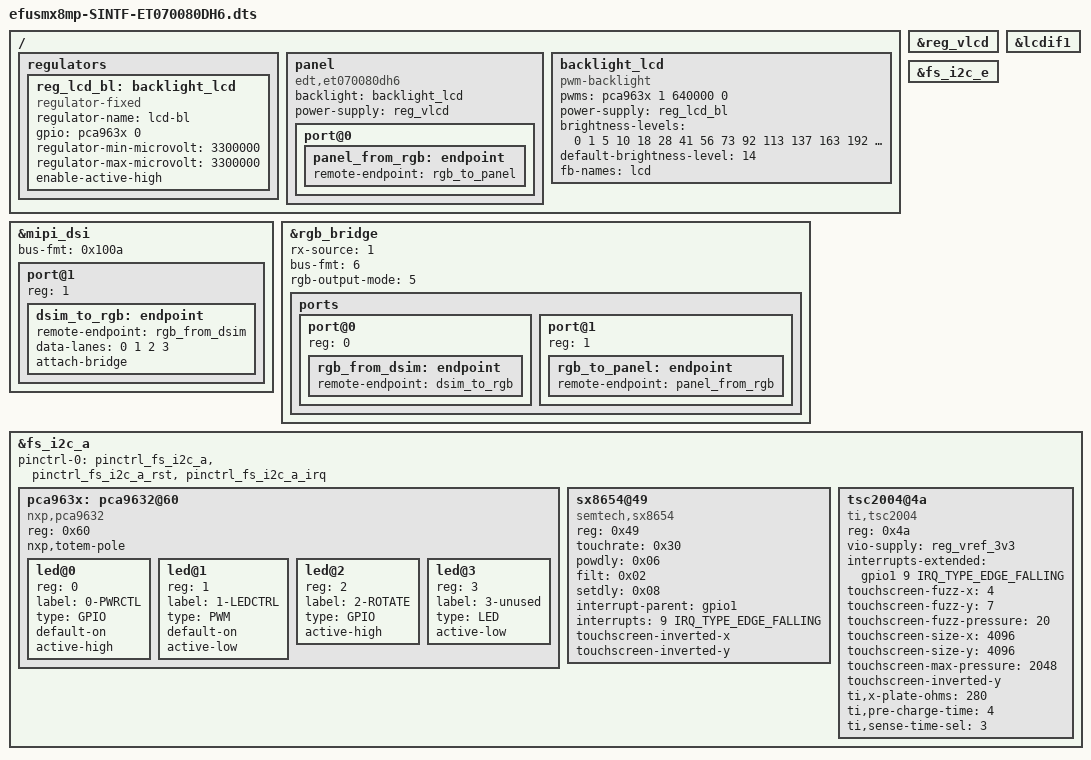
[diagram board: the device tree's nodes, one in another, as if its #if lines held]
/*
* Copyright (C) 2023 F&S Elektronik Systeme GmbH
*
* This program is free software; you can redistribute it and/or modify
* it under the terms of the GNU General Public License version 2 as
* published by the Free Software Foundation.
*/

/dts-v1/;

//#define CONFIG_EFUSMX8MP_4WTOUCH_SX8655_RGBADAPTER_EDT1
#define CONFIG_EFUSMX8MP_4WTOUCH_TSC2004_RGBADAPTER_EDT2

#include "efusmx8mp-SINTF.dts"

/{

	regulators {
    	reg_lcd_bl: backlight_lcd {
			compatible = "regulator-fixed";
			regulator-name = "lcd-bl";
			gpio = <&pca963x 0 0>;
			regulator-min-microvolt = <3300000>;
			regulator-max-microvolt = <3300000>;
			enable-active-high;
		};
    };

    panel: panel {
		compatible = "edt,et070080dh6";
		backlight = <&backlight_lcd>;
		power-supply = <&reg_vlcd>;

		port@0 {
			panel_from_rgb: endpoint {
				remote-endpoint = <&rgb_to_panel>;
			};
		};
	};

    backlight_lcd: backlight_lcd {
		compatible = "pwm-backlight";
		pwms = <&pca963x 1 640000 0>;
		power-supply = <&reg_lcd_bl>;
		brightness-levels = <0 1 5 10 18 28 41 56
				     73 92 113 137 163 192 222 255>;
		default-brightness-level = <14>;
		fb-names = "lcd";
	};
};

&reg_vlcd { status = "okay"; };
&lcdif1 { status = "okay"; };

&mipi_dsi {

	status = "okay";

	bus-fmt = <0x100a>; /*MEDIA_BUS_FMT_RGB888_1X24*/
	port@1{
		reg = <1>;
		dsim_to_rgb: endpoint {
			remote-endpoint = <&rgb_from_dsim>;
			data-lanes = <0 1 2 3>;
			attach-bridge;
		};
	};
};

&fs_i2c_e { status = "okay"; };

&rgb_bridge {

    /* 0 = LVDS, 1 = MIPI, 2 = TTL */
    rx-source = /bits/ 8 <1>;
    /* optional: normally taken from simple panel display but can be
        * overwritten by bus-fmt flag: 6 = RGB666, 8 = RGB888
        */
    bus-fmt = /bits/ 8 <6>;
    /* PCLK will inverted because dotclock polarity from sec_mipi_dsim-imx
        * is set to neg edge. The display needs dotclock pos edge therefore
        * we inverte dotclock polarity.
        */
    //pclk-invert;

    /* s. datasheet reg 0x856d rgd_ttl_tx_24B_mode_sel
        * 	0 - output 3 channel 8 bit data
        * 	1 - output 2 channel 12 bit data
        *  ...
        *  4 - output 3 channel 6 bit (high 18 bit active)
        *  5 - output 3 channel 6 bit (low 18 bit active)
        *  ...
        * */
    rgb-output-mode = /bits/ 8 <5>;

	status = "okay";
    ports {
        #address-cells = <1>;
        #size-cells = <0>;
        port@0 {
            reg = <0>;
            rgb_from_dsim: endpoint {
                remote-endpoint = <&dsim_to_rgb>;
            };
        };
        port@1 {
            reg = <1>;
            rgb_to_panel: endpoint {
                remote-endpoint = <&panel_from_rgb>;
            };
        };
    };
};

&fs_i2c_a {
    status = "okay";
    pinctrl-0 = <&pinctrl_fs_i2c_a>, <&pinctrl_fs_i2c_a_rst>, <&pinctrl_fs_i2c_a_irq>;

    pca963x: pca9632@60 { /* LED-driver */
		compatible = "nxp,pca9632";
		reg = <0x60>;
		nxp,totem-pole;
		#address-cells = <1>;
		#size-cells = <0>;
		#pwm-cells = <3>;
		#gpio-cells = <2>;
		led@0 {
			reg = <0>;
			label = "0-PWRCTL";
			type = "GPIO";
			default-on;		/* or: keep-value */
			active-high;
		};
		led@1 {
			reg = <1>;
			label = "1-LEDCTRL";
			type = "PWM";
			default-on;		/* or: keep-value */
			active-low;
		};
		led@2 {
			reg = <2>;
			label = "2-ROTATE";
			type = "GPIO";
			active-high;		/* optionally: keep value */
		};
		led@3 {
			reg = <3>;
			label = "3-unused";
			type = "LED";
			active-low;
		};
	};

#ifdef CONFIG_EFUSMX8MP_4WTOUCH_SX8655_RGBADAPTER_EDT1
	/* 4/5 wire analog resistive touch on RGB-Adapter */
	sx8654@49 {
		compatible = "semtech,sx8654";
		reg = <0x49>;
		touchrate = <0x30>;
		powdly = <0x06>;
		filt = <0x02>;
		setdly = <0x08>;
		interrupt-parent = <&gpio1>;
		interrupts = <9 IRQ_TYPE_EDGE_FALLING>;
		//reset-gpio = <&gpio1 8 GPIO_ACTIVE_LOW>;
		/* using global touchscreen_parse_properties, instead of
		 * specific parsing.
		 */
		touchscreen-inverted-x;
		touchscreen-inverted-y;
	};
#endif

#ifdef CONFIG_EFUSMX8MP_4WTOUCH_TSC2004_RGBADAPTER_EDT2
	tsc2004@4a {
		compatible = "ti,tsc2004";
		reg = <0x4a>;
		vio-supply = <&reg_vref_3v3>;

		interrupts-extended = <&gpio1 9 IRQ_TYPE_EDGE_FALLING>;
		touchscreen-fuzz-x = <4>;
		touchscreen-fuzz-y = <7>;
		touchscreen-fuzz-pressure = <20>;
		touchscreen-size-x = <4096>;
		touchscreen-size-y = <4096>;
		touchscreen-max-pressure = <2048>;
		touchscreen-inverted-y;
		ti,x-plate-ohms = <280>;
		ti,pre-charge-time = <4>;
		ti,sense-time-sel = <3>;
		//ti,esd-recovery-timeout-ms = <8000>;
	};
#endif
};



